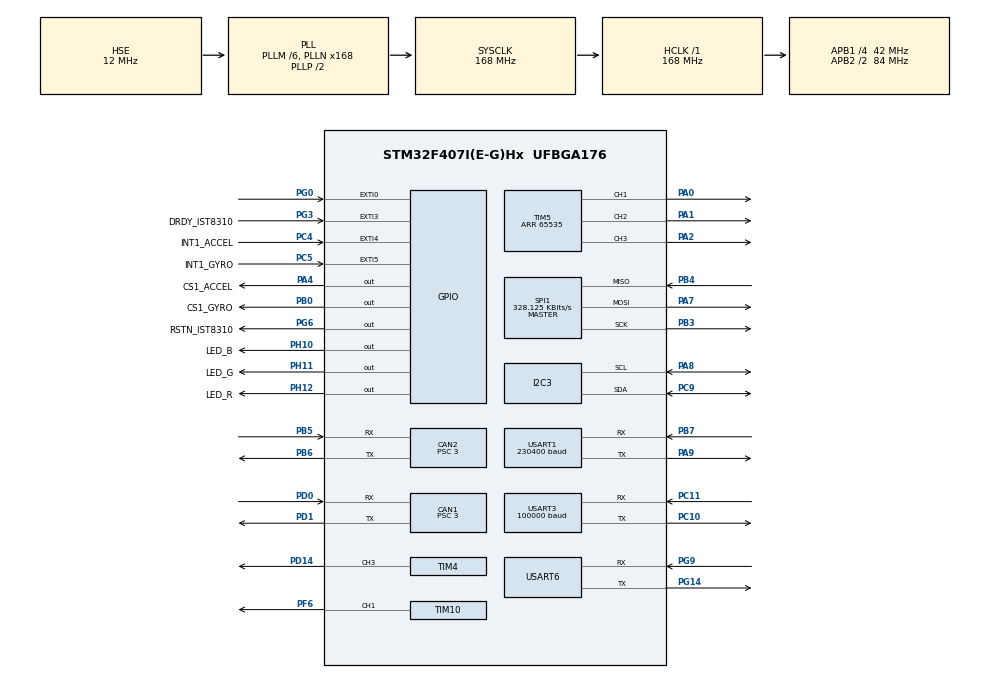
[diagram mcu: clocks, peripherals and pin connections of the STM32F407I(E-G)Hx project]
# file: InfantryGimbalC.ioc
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CAN1.ABOM=ENABLE
CAN1.AWUM=ENABLE
CAN1.BS1=CAN_BS1_10TQ
CAN1.BS2=CAN_BS2_3TQ
CAN1.CalculateBaudRate=1000000
CAN1.CalculateTimeBit=1000
CAN1.CalculateTimeQuantum=71.42857142857143
CAN1.NART=ENABLE
CAN1.Prescaler=3
CAN2.ABOM=ENABLE
CAN2.AWUM=ENABLE
CAN2.BS1=CAN_BS1_10TQ
CAN2.BS2=CAN_BS2_3TQ
CAN2.CalculateBaudRate=1000000
CAN2.CalculateTimeBit=1000
CAN2.CalculateTimeQuantum=71.42857142857143
CAN2.NART=ENABLE
CAN2.Prescaler=3
Dma.Request0=SPI1_RX
Dma.Request1=SPI1_TX
Dma.Request2=USART3_RX
Dma.Request3=USART6_RX
Dma.Request4=USART6_TX
Dma.Request5=USART1_RX
Dma.SPI1_RX.0.Direction=DMA_PERIPH_TO_MEMORY
Dma.SPI1_RX.0.FIFOMode=DMA_FIFOMODE_DISABLE
Dma.SPI1_RX.0.Instance=DMA2_Stream2
Dma.SPI1_RX.0.MemDataAlignment=DMA_MDATAALIGN_BYTE
Dma.SPI1_RX.0.MemInc=DMA_MINC_ENABLE
Dma.SPI1_RX.0.Mode=DMA_NORMAL
Dma.SPI1_RX.0.PeriphDataAlignment=DMA_PDATAALIGN_BYTE
Dma.SPI1_RX.0.PeriphInc=DMA_PINC_DISABLE
Dma.SPI1_RX.0.Priority=DMA_PRIORITY_VERY_HIGH
Dma.SPI1_TX.1.Direction=DMA_MEMORY_TO_PERIPH
Dma.SPI1_TX.1.FIFOMode=DMA_FIFOMODE_DISABLE
Dma.SPI1_TX.1.Instance=DMA2_Stream3
Dma.SPI1_TX.1.MemDataAlignment=DMA_MDATAALIGN_BYTE
Dma.SPI1_TX.1.MemInc=DMA_MINC_ENABLE
Dma.SPI1_TX.1.Mode=DMA_NORMAL
Dma.SPI1_TX.1.PeriphDataAlignment=DMA_PDATAALIGN_BYTE
Dma.SPI1_TX.1.PeriphInc=DMA_PINC_DISABLE
Dma.SPI1_TX.1.Priority=DMA_PRIORITY_HIGH
Dma.USART1_RX.5.Direction=DMA_PERIPH_TO_MEMORY
Dma.USART1_RX.5.FIFOMode=DMA_FIFOMODE_DISABLE
Dma.USART1_RX.5.Instance=DMA2_Stream5
Dma.USART1_RX.5.MemDataAlignment=DMA_MDATAALIGN_BYTE
Dma.USART1_RX.5.MemInc=DMA_MINC_ENABLE
Dma.USART1_RX.5.Mode=DMA_NORMAL
Dma.USART1_RX.5.PeriphDataAlignment=DMA_PDATAALIGN_BYTE
Dma.USART1_RX.5.PeriphInc=DMA_PINC_DISABLE
Dma.USART1_RX.5.Priority=DMA_PRIORITY_LOW
Dma.USART3_RX.2.Direction=DMA_PERIPH_TO_MEMORY
Dma.USART3_RX.2.FIFOMode=DMA_FIFOMODE_DISABLE
Dma.USART3_RX.2.Instance=DMA1_Stream1
Dma.USART3_RX.2.MemDataAlignment=DMA_MDATAALIGN_BYTE
Dma.USART3_RX.2.MemInc=DMA_MINC_ENABLE
Dma.USART3_RX.2.Mode=DMA_NORMAL
Dma.USART3_RX.2.PeriphDataAlignment=DMA_PDATAALIGN_BYTE
Dma.USART3_RX.2.PeriphInc=DMA_PINC_DISABLE
Dma.USART3_RX.2.Priority=DMA_PRIORITY_HIGH
Dma.USART6_RX.3.Direction=DMA_PERIPH_TO_MEMORY
Dma.USART6_RX.3.FIFOMode=DMA_FIFOMODE_DISABLE
Dma.USART6_RX.3.Instance=DMA2_Stream1
Dma.USART6_RX.3.MemDataAlignment=DMA_MDATAALIGN_BYTE
Dma.USART6_RX.3.MemInc=DMA_MINC_ENABLE
Dma.USART6_RX.3.Mode=DMA_CIRCULAR
Dma.USART6_RX.3.PeriphDataAlignment=DMA_PDATAALIGN_BYTE
Dma.USART6_RX.3.PeriphInc=DMA_PINC_DISABLE
Dma.USART6_RX.3.Priority=DMA_PRIORITY_MEDIUM
Dma.USART6_TX.4.Direction=DMA_MEMORY_TO_PERIPH
Dma.USART6_TX.4.FIFOMode=DMA_FIFOMODE_DISABLE
Dma.USART6_TX.4.Instance=DMA2_Stream6
Dma.USART6_TX.4.MemDataAlignment=DMA_MDATAALIGN_BYTE
Dma.USART6_TX.4.MemInc=DMA_MINC_ENABLE
Dma.USART6_TX.4.Mode=DMA_NORMAL
Dma.USART6_TX.4.PeriphDataAlignment=DMA_PDATAALIGN_BYTE
Dma.USART6_TX.4.PeriphInc=DMA_PINC_DISABLE
Dma.USART6_TX.4.Priority=DMA_PRIORITY_MEDIUM
FREERTOS.BinarySemaphores01=RemoteSem,Dynamic,NULL
FREERTOS.Events01=refereeEvent,Dynamic,NULL
FREERTOS.INCLUDE_pcTaskGetTaskName=1
FREERTOS.INCLUDE_xTaskGetHandle=1
FREERTOS.Queues01=can1Queue,512,size10_t,0,Dynamic,NULL,NULL;can2Queue,512,size10_t,0,Dynamic,NULL,NULL
FREERTOS.Tasks01=defaultTask,24,256,StartDefaultTask,Default,NULL,Dynamic,NULL,NULL;ledTask,8,256,Led_Task,As weak,NULL,Dynamic,NULL,NULL;buzzerTask,8,256,Buzzer_Task,As weak,NULL,Dynamic,NULL,NULL;imuTask,55,1024,Gyro_task,As weak,NULL,Dynamic,NULL,NULL;remoteTask,55,256,Remote_Task,As weak,NULL,Dynamic,NULL,NULL;communicateTask,55,256,Communicate_Task,As weak,NULL,Dynamic,NULL,NULL;chassisTask,55,2048,Chassis_Task,As weak,NULL,Dynamic,NULL,NULL;communicate2Tas,55,256,Communicate2_Task,As weak,NULL,Dynamic,NULL,NULL;judgeUnpackTask,55,256,Judge_Unpack_Task,As weak,NULL,Dynamic,NULL,NULL;stuinteractiveT,8,256,StuInteractive_Task,As weak,NULL,Dynamic,NULL,NULL;powerTask,55,256,PowerTask,As weak,NULL,Dynamic,NULL,NULL;communicate3Tas,8,256,Communicate3_Task,As weak,NULL,Dynamic,NULL,NULL;lostCounterTask,8,256,LostCounter_Task,As weak,NULL,Dynamic,NULL,NULL
FREERTOS.configGENERATE_RUN_TIME_STATS=1
FREERTOS.configMINIMAL_STACK_SIZE=256
FREERTOS.configTOTAL_HEAP_SIZE=80000
FREERTOS.configUSE_NEWLIB_REENTRANT=1
I2C3.I2C_Mode=I2C_Fast
IWDG.Prescaler=IWDG_PRESCALER_64
IWDG.Reload=625
Mcu.Family=STM32F4
Mcu.Name=STM32F407I(E-G)Hx
Mcu.Package=UFBGA176
NVIC.CAN1_RX0_IRQn=true\:5\:0\:false\:false\:true\:true\:true\:true\:true
NVIC.CAN2_RX0_IRQn=true\:5\:0\:false\:false\:true\:true\:true\:true\:true
NVIC.DMA1_Stream1_IRQn=true\:5\:0\:false\:false\:true\:true\:false\:true\:true
NVIC.DMA2_Stream1_IRQn=true\:5\:0\:false\:false\:true\:true\:false\:true\:true
NVIC.DMA2_Stream2_IRQn=true\:5\:0\:false\:false\:true\:false\:false\:true\:true
NVIC.DMA2_Stream3_IRQn=true\:5\:0\:false\:false\:true\:true\:false\:true\:true
NVIC.DMA2_Stream5_IRQn=true\:5\:0\:false\:false\:true\:true\:false\:true\:true
NVIC.DMA2_Stream6_IRQn=true\:5\:0\:false\:false\:true\:true\:false\:true\:true
NVIC.EXTI0_IRQn=true\:5\:0\:false\:false\:true\:true\:true\:true\:true
NVIC.EXTI3_IRQn=true\:5\:0\:false\:false\:true\:true\:true\:true\:true
NVIC.EXTI4_IRQn=true\:5\:0\:false\:false\:true\:true\:true\:true\:true
NVIC.EXTI9_5_IRQn=true\:5\:0\:false\:false\:true\:true\:true\:true\:true
NVIC.PriorityGroup=NVIC_PRIORITYGROUP_4
NVIC.TIM7_IRQn=true\:15\:0\:false\:false\:true\:false\:false\:true\:true
NVIC.TimeBase=TIM7_IRQn
NVIC.TimeBaseIP=TIM7
NVIC.USART1_IRQn=true\:5\:0\:false\:false\:true\:true\:true\:true\:true
NVIC.USART3_IRQn=true\:5\:0\:false\:false\:true\:true\:true\:true\:true
NVIC.USART6_IRQn=true\:5\:0\:false\:false\:true\:true\:true\:true\:true
PA0-WKUP.Signal=S_TIM5_CH1
PA1.Signal=S_TIM5_CH2
PA13.Mode=Serial_Wire
PA13.Signal=SYS_JTMS-SWDIO
PA14.Mode=Serial_Wire
PA14.Signal=SYS_JTCK-SWCLK
PA2.Signal=S_TIM5_CH3
PA4.GPIO_Label=CS1_ACCEL
PA4.GPIO_PuPd=GPIO_PULLUP
PA4.GPIO_Speed=GPIO_SPEED_FREQ_HIGH
PA4.PinState=GPIO_PIN_SET
PA4.Signal=GPIO_Output
PA7.Mode=Full_Duplex_Master
PA7.Signal=SPI1_MOSI
PA8.Mode=I2C
PA8.Signal=I2C3_SCL
PA9.Mode=Asynchronous
PA9.Signal=USART1_TX
PB0.GPIO_Label=CS1_GYRO
PB0.GPIO_PuPd=GPIO_PULLUP
PB0.GPIO_Speed=GPIO_SPEED_FREQ_HIGH
PB0.PinState=GPIO_PIN_SET
PB0.Signal=GPIO_Output
PB3.Mode=Full_Duplex_Master
PB3.Signal=SPI1_SCK
PB4.Mode=Full_Duplex_Master
PB4.Signal=SPI1_MISO
PB5.Mode=CAN_Activate
PB5.Signal=CAN2_RX
PB6.Mode=CAN_Activate
PB6.Signal=CAN2_TX
PB7.Mode=Asynchronous
PB7.Signal=USART1_RX
PC10.Mode=Asynchronous
PC10.Signal=USART3_TX
PC11.Mode=Asynchronous
PC11.Signal=USART3_RX
PC4.GPIO_Label=INT1_ACCEL
PC4.GPIO_ModeDefaultEXTI=GPIO_MODE_IT_FALLING
PC4.GPIO_PuPd=GPIO_PULLUP
PC4.Signal=GPXTI4
PC5.GPIO_Label=INT1_GYRO
PC5.GPIO_ModeDefaultEXTI=GPIO_MODE_IT_FALLING
PC5.GPIO_PuPd=GPIO_PULLUP
PC5.Signal=GPXTI5
PC9.Mode=I2C
PC9.Signal=I2C3_SDA
PD0.Mode=CAN_Activate
PD0.Signal=CAN1_RX
PD1.Mode=CAN_Activate
PD1.Signal=CAN1_TX
PD14.Signal=S_TIM4_CH3
PF6.GPIO_PuPd=GPIO_PULLUP
PF6.GPIO_Speed=GPIO_SPEED_FREQ_HIGH
PF6.Signal=S_TIM10_CH1
PG0.GPIO_ModeDefaultEXTI=GPIO_MODE_IT_FALLING
PG0.GPIO_PuPd=GPIO_PULLUP
PG0.Signal=GPXTI0
PG14.Mode=Asynchronous
PG14.Signal=USART6_TX
PG3.GPIO_Label=DRDY_IST8310
PG3.GPIO_ModeDefaultEXTI=GPIO_MODE_IT_FALLING
PG3.GPIO_PuPd=GPIO_PULLUP
PG3.Signal=GPXTI3
PG6.GPIO_Label=RSTN_IST8310
PG6.GPIO_PuPd=GPIO_PULLUP
PG6.GPIO_Speed=GPIO_SPEED_FREQ_MEDIUM
PG6.PinState=GPIO_PIN_SET
PG6.Signal=GPIO_Output
PG9.Mode=Asynchronous
PG9.Signal=USART6_RX
PH0-OSC_IN.Mode=HSE-External-Oscillator
PH0-OSC_IN.Signal=RCC_OSC_IN
PH1-OSC_OUT.Mode=HSE-External-Oscillator
PH1-OSC_OUT.Signal=RCC_OSC_OUT
PH10.GPIO_Label=LED_B
PH10.Signal=GPIO_Output
PH11.GPIO_Label=LED_G
PH11.Signal=GPIO_Output
PH12.GPIO_Label=LED_R
PH12.Signal=GPIO_Output
ProjectManager.HeapSize=0x200
ProjectManager.StackSize=0x400
ProjectManager.TargetToolchain=STM32CubeIDE
RCC.48MHZClocksFreq_Value=84000000
RCC.AHBFreq_Value=168000000
RCC.APB1CLKDivider=RCC_HCLK_DIV4
RCC.APB1Freq_Value=42000000
RCC.APB1TimFreq_Value=84000000
RCC.APB2CLKDivider=RCC_HCLK_DIV2
RCC.APB2Freq_Value=84000000
RCC.APB2TimFreq_Value=168000000
RCC.CortexFreq_Value=168000000
RCC.HCLKFreq_Value=168000000
RCC.HSE_VALUE=12000000
RCC.HSI_VALUE=16000000
RCC.LSE_VALUE=32768
RCC.PLLM=6
RCC.PLLN=168
RCC.PLLSourceVirtual=RCC_PLLSOURCE_HSE
RCC.SYSCLKFreq_VALUE=168000000
RCC.SYSCLKSource=RCC_SYSCLKSOURCE_PLLCLK
RCC.VCOOutputFreq_Value=336000000
SH.S_TIM10_CH1.0=TIM10_CH1,PWM Generation1 CH1
SH.S_TIM4_CH3.0=TIM4_CH3,PWM Generation3 CH3
SH.S_TIM5_CH1.0=TIM5_CH1,PWM Generation1 CH1
SH.S_TIM5_CH2.0=TIM5_CH2,PWM Generation2 CH2
SH.S_TIM5_CH3.0=TIM5_CH3,PWM Generation3 CH3
SPI1.BaudRatePrescaler=SPI_BAUDRATEPRESCALER_256
SPI1.CLKPhase=SPI_PHASE_2EDGE
SPI1.CLKPolarity=SPI_POLARITY_HIGH
SPI1.CalculateBaudRate=328.125 KBits/s
SPI1.Direction=SPI_DIRECTION_2LINES
SPI1.Mode=SPI_MODE_MASTER
SPI1.VirtualType=VM_MASTER
STMicroelectronics.X-CUBE-ALGOBUILD.1.3.0.LibraryCcDSPOoLibraryJjDSPOoLibrary=true
TIM10.Channel=TIM_CHANNEL_1
TIM10.Period=4999
TIM4.Channel-PWM\ Generation3\ CH3=TIM_CHANNEL_3
TIM4.Period=999
TIM4.Prescaler=83
TIM4.Pulse-PWM\ Generation3\ CH3=500
TIM5.Channel-PWM\ Generation1\ CH1=TIM_CHANNEL_1
TIM5.Channel-PWM\ Generation2\ CH2=TIM_CHANNEL_2
TIM5.Channel-PWM\ Generation3\ CH3=TIM_CHANNEL_3
TIM5.Period=65535
USART1.BaudRate=230400
USART1.Mode=MODE_RX
USART1.VirtualMode=VM_ASYNC
USART3.BaudRate=100000
USART3.Mode=MODE_RX
USART3.Parity=PARITY_EVEN
USART3.VirtualMode=VM_ASYNC
USART3.WordLength=WORDLENGTH_9B
USART6.VirtualMode=VM_ASYNC
VP_FREERTOS_VS_CMSIS_V2.Mode=CMSIS_V2
VP_IWDG_VS_IWDG.Mode=IWDG_Activate
VP_STMicroelectronics.X-CUBE-ALGOBUILD_VS_DSPOoLibraryJjLibrary_1.3.0_1.3.0.Mode=DSPOoLibraryJjLibrary
VP_SYS_VS_tim7.Mode=TIM7
VP_TIM10_VS_ClockSourceINT.Mode=Enable_Timer
VP_TIM4_VS_ClockSourceINT.Mode=Internal
VP_TIM5_VS_ClockSourceINT.Mode=Internal
board=custom

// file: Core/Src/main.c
/* USER CODE BEGIN Header */
/**
  ******************************************************************************
  * @file           : main.c
  * @brief          : Main program body
  ******************************************************************************
  * @attention
  *
  * Copyright (c) 2023 STMicroelectronics.
  * All rights reserved.
  *
  * This software is licensed under terms that can be found in the LICENSE file
  * in the root directory of this software component.
  * If no LICENSE file comes with this software, it is provided AS-IS.
  *
  ******************************************************************************
  */
/* USER CODE END Header */
#include "main.h"
#include "cmsis_os.h"
#include "can.h"
#include "dma.h"
#include "i2c.h"
#include "iwdg.h"
#include "spi.h"
#include "tim.h"
#include "usart.h"
#include "gpio.h"

/* USER CODE BEGIN Includes */
#include "BMI088driver.h"
#include "bsp_dwt.h"
#include "bsp_can.h"
/* USER CODE END Includes */

void SystemClock_Config(void);
void MX_FREERTOS_Init(void);

/* USER CODE BEGIN 0 */
uint8_t Buffer[1];
/* USER CODE END 0 */

int main(void)
{
  /* USER CODE BEGIN 1 */
//修复openocd初始化时钟问�??
    __HAL_RCC_SYSCLK_CONFIG(RCC_SYSCLKSOURCE_HSI);
  /* USER CODE END 1 */

  /* MCU Configuration--------------------------------------------------------*/

  /* Reset of all peripherals, Initializes the Flash interface and the Systick. */
  HAL_Init();

  /* Configure the system clock */
  SystemClock_Config();

  /* Initialize all configured peripherals */
  MX_GPIO_Init();
  MX_DMA_Init();
  MX_TIM4_Init();
  MX_SPI1_Init();
  MX_I2C3_Init();
  MX_TIM10_Init();
  MX_TIM5_Init();
  MX_CAN1_Init();
  MX_CAN2_Init();
  MX_USART3_UART_Init();
  MX_USART6_UART_Init();
  MX_IWDG_Init();
  MX_USART1_UART_Init();
  /* USER CODE BEGIN 2 */
    DWT_Init(168);
    while (BMI088_init(&hspi1, 0) != BMI088_NO_ERROR)
        ;
    HAL_TIM_PWM_Start(&htim4,TIM_CHANNEL_3);
    CanInit();
    HAL_UARTEx_ReceiveToIdle_DMA(&huart1,(uint8_t *)Buffer, 1);
   // HAL_UART_Receive_IT(&huart1, (uint8_t *)Buffer, 1);
  /* USER CODE END 2 */

  /* Init scheduler */
  osKernelInitialize();  /* Call init function for freertos objects (in freertos.c) */
  MX_FREERTOS_Init();

  /* Start scheduler */
  osKernelStart();

  /* We should never get here as control is now taken by the scheduler */
  /* Infinite loop */
  while (1)
  {

  }
}

void SystemClock_Config(void)
{
  RCC_OscInitTypeDef RCC_OscInitStruct = {0};
  RCC_ClkInitTypeDef RCC_ClkInitStruct = {0};

  /** Configure the main internal regulator output voltage
  */
  __HAL_RCC_PWR_CLK_ENABLE();
  __HAL_PWR_VOLTAGESCALING_CONFIG(PWR_REGULATOR_VOLTAGE_SCALE1);

  /** Initializes the RCC Oscillators according to the specified parameters
  * in the RCC_OscInitTypeDef structure.
  */
  RCC_OscInitStruct.OscillatorType = RCC_OSCILLATORTYPE_LSI|RCC_OSCILLATORTYPE_HSE;
  RCC_OscInitStruct.HSEState = RCC_HSE_ON;
  RCC_OscInitStruct.LSIState = RCC_LSI_ON;
  RCC_OscInitStruct.PLL.PLLState = RCC_PLL_ON;
  RCC_OscInitStruct.PLL.PLLSource = RCC_PLLSOURCE_HSE;
  RCC_OscInitStruct.PLL.PLLM = 6;
  RCC_OscInitStruct.PLL.PLLN = 168;
  RCC_OscInitStruct.PLL.PLLP = RCC_PLLP_DIV2;
  RCC_OscInitStruct.PLL.PLLQ = 4;
  if (HAL_RCC_OscConfig(&RCC_OscInitStruct) != HAL_OK)
  {
    Error_Handler();
  }

  /** Initializes the CPU, AHB and APB buses clocks
  */
  RCC_ClkInitStruct.ClockType = RCC_CLOCKTYPE_HCLK|RCC_CLOCKTYPE_SYSCLK
                              |RCC_CLOCKTYPE_PCLK1|RCC_CLOCKTYPE_PCLK2;
  RCC_ClkInitStruct.SYSCLKSource = RCC_SYSCLKSOURCE_PLLCLK;
  RCC_ClkInitStruct.AHBCLKDivider = RCC_SYSCLK_DIV1;
  RCC_ClkInitStruct.APB1CLKDivider = RCC_HCLK_DIV4;
  RCC_ClkInitStruct.APB2CLKDivider = RCC_HCLK_DIV2;

  if (HAL_RCC_ClockConfig(&RCC_ClkInitStruct, FLASH_LATENCY_5) != HAL_OK)
  {
    Error_Handler();
  }
}

void HAL_TIM_PeriodElapsedCallback(TIM_HandleTypeDef *htim)
{
  if (htim->Instance == TIM7) {
    HAL_IncTick();
  }
}

void Error_Handler(void)
{
  __disable_irq();
  while (1)
  {
  }
}

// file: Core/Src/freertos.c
/* USER CODE BEGIN Header */
/**
  ******************************************************************************
  * File Name          : freertos.c
  * Description        : Code for freertos applications
  ******************************************************************************
  * @attention
  *
  * Copyright (c) 2023 STMicroelectronics.
  * All rights reserved.
  *
  * This software is licensed under terms that can be found in the LICENSE file
  * in the root directory of this software component.
  * If no LICENSE file comes with this software, it is provided AS-IS.
  *
  ******************************************************************************
  */
/* USER CODE END Header */

#include "FreeRTOS.h"
#include "task.h"
#include "main.h"
#include "cmsis_os.h"

/* Definitions for defaultTask */
osThreadId_t defaultTaskHandle;
const osThreadAttr_t defaultTask_attributes = {
  .name = "defaultTask",
  .stack_size = 256 * 4,
  .priority = (osPriority_t) osPriorityNormal,
};
/* Definitions for ledTask */
osThreadId_t ledTaskHandle;
const osThreadAttr_t ledTask_attributes = {
  .name = "ledTask",
  .stack_size = 256 * 4,
  .priority = (osPriority_t) osPriorityLow,
};
/* Definitions for buzzerTask */
osThreadId_t buzzerTaskHandle;
const osThreadAttr_t buzzerTask_attributes = {
  .name = "buzzerTask",
  .stack_size = 256 * 4,
  .priority = (osPriority_t) osPriorityLow,
};
/* Definitions for imuTask */
osThreadId_t imuTaskHandle;
const osThreadAttr_t imuTask_attributes = {
  .name = "imuTask",
  .stack_size = 1024 * 4,
  .priority = (osPriority_t) osPriorityRealtime7,
};
/* Definitions for remoteTask */
osThreadId_t remoteTaskHandle;
const osThreadAttr_t remoteTask_attributes = {
  .name = "remoteTask",
  .stack_size = 256 * 4,
  .priority = (osPriority_t) osPriorityRealtime7,
};
/* Definitions for communicateTask */
osThreadId_t communicateTaskHandle;
const osThreadAttr_t communicateTask_attributes = {
  .name = "communicateTask",
  .stack_size = 256 * 4,
  .priority = (osPriority_t) osPriorityRealtime7,
};
/* Definitions for chassisTask */
osThreadId_t chassisTaskHandle;
const osThreadAttr_t chassisTask_attributes = {
  .name = "chassisTask",
  .stack_size = 2048 * 4,
  .priority = (osPriority_t) osPriorityRealtime7,
};
/* Definitions for communicate2Tas */
osThreadId_t communicate2TasHandle;
const osThreadAttr_t communicate2Tas_attributes = {
  .name = "communicate2Tas",
  .stack_size = 256 * 4,
  .priority = (osPriority_t) osPriorityRealtime7,
};
/* Definitions for judgeUnpackTask */
osThreadId_t judgeUnpackTaskHandle;
const osThreadAttr_t judgeUnpackTask_attributes = {
  .name = "judgeUnpackTask",
  .stack_size = 256 * 4,
  .priority = (osPriority_t) osPriorityRealtime7,
};
/* Definitions for stuinteractiveT */
osThreadId_t stuinteractiveTHandle;
const osThreadAttr_t stuinteractiveT_attributes = {
  .name = "stuinteractiveT",
  .stack_size = 256 * 4,
  .priority = (osPriority_t) osPriorityLow,
};
/* Definitions for powerTask */
osThreadId_t powerTaskHandle;
const osThreadAttr_t powerTask_attributes = {
  .name = "powerTask",
  .stack_size = 256 * 4,
  .priority = (osPriority_t) osPriorityRealtime7,
};
/* Definitions for communicate3Tas */
osThreadId_t communicate3TasHandle;
const osThreadAttr_t communicate3Tas_attributes = {
  .name = "communicate3Tas",
  .stack_size = 256 * 4,
  .priority = (osPriority_t) osPriorityLow,
};
/* Definitions for lostCounterTask */
osThreadId_t lostCounterTaskHandle;
const osThreadAttr_t lostCounterTask_attributes = {
  .name = "lostCounterTask",
  .stack_size = 256 * 4,
  .priority = (osPriority_t) osPriorityLow,
};
/* Definitions for can1Queue */
osMessageQueueId_t can1QueueHandle;
const osMessageQueueAttr_t can1Queue_attributes = {
  .name = "can1Queue"
};
/* Definitions for can2Queue */
osMessageQueueId_t can2QueueHandle;
const osMessageQueueAttr_t can2Queue_attributes = {
  .name = "can2Queue"
};
/* Definitions for RemoteSem */
osSemaphoreId_t RemoteSemHandle;
const osSemaphoreAttr_t RemoteSem_attributes = {
  .name = "RemoteSem"
};
/* Definitions for refereeEvent */
osEventFlagsId_t refereeEventHandle;
const osEventFlagsAttr_t refereeEvent_attributes = {
  .name = "refereeEvent"
};

void StartDefaultTask(void *argument);
void Led_Task(void *argument);
void Buzzer_Task(void *argument);
void Gyro_task(void *argument);
void Remote_Task(void *argument);
void Communicate_Task(void *argument);
void Chassis_Task(void *argument);
void Communicate2_Task(void *argument);
void Judge_Unpack_Task(void *argument);
void StuInteractive_Task(void *argument);
void PowerTask(void *argument);
void Communicate3_Task(void *argument);
void LostCounter_Task(void *argument);

void MX_FREERTOS_Init(void); /* (MISRA C 2004 rule 8.1) */

/* Hook prototypes */
void configureTimerForRunTimeStats(void);
unsigned long getRunTimeCounterValue(void);

/* USER CODE BEGIN 1 */
/* Functions needed when configGENERATE_RUN_TIME_STATS is on */
__weak void configureTimerForRunTimeStats(void)
{

}

__weak unsigned long getRunTimeCounterValue(void)
{
return 0;
}
/* USER CODE END 1 */

void MX_FREERTOS_Init(void) {

  /* Create the semaphores(s) */
  /* creation of RemoteSem */
  RemoteSemHandle = osSemaphoreNew(1, 1, &RemoteSem_attributes);

  /* Create the queue(s) */
  /* creation of can1Queue */
  can1QueueHandle = osMessageQueueNew (512, sizeof(size10_t), &can1Queue_attributes);

  /* creation of can2Queue */
  can2QueueHandle = osMessageQueueNew (512, sizeof(size10_t), &can2Queue_attributes);

  /* Create the thread(s) */
  /* creation of defaultTask */
  defaultTaskHandle = osThreadNew(StartDefaultTask, NULL, &defaultTask_attributes);

  /* creation of ledTask */
  ledTaskHandle = osThreadNew(Led_Task, NULL, &ledTask_attributes);

  /* creation of buzzerTask */
  buzzerTaskHandle = osThreadNew(Buzzer_Task, NULL, &buzzerTask_attributes);

  /* creation of imuTask */
  imuTaskHandle = osThreadNew(Gyro_task, NULL, &imuTask_attributes);

  /* creation of remoteTask */
  remoteTaskHandle = osThreadNew(Remote_Task, NULL, &remoteTask_attributes);

  /* creation of communicateTask */
  communicateTaskHandle = osThreadNew(Communicate_Task, NULL, &communicateTask_attributes);

  /* creation of chassisTask */
  chassisTaskHandle = osThreadNew(Chassis_Task, NULL, &chassisTask_attributes);

  /* creation of communicate2Tas */
  communicate2TasHandle = osThreadNew(Communicate2_Task, NULL, &communicate2Tas_attributes);

  /* creation of judgeUnpackTask */
  judgeUnpackTaskHandle = osThreadNew(Judge_Unpack_Task, NULL, &judgeUnpackTask_attributes);

  /* creation of stuinteractiveT */
  stuinteractiveTHandle = osThreadNew(StuInteractive_Task, NULL, &stuinteractiveT_attributes);

  /* creation of powerTask */
  powerTaskHandle = osThreadNew(PowerTask, NULL, &powerTask_attributes);

  /* creation of communicate3Tas */
  communicate3TasHandle = osThreadNew(Communicate3_Task, NULL, &communicate3Tas_attributes);

  /* creation of lostCounterTask */
  lostCounterTaskHandle = osThreadNew(LostCounter_Task, NULL, &lostCounterTask_attributes);

  /* Create the event(s) */
  /* creation of refereeEvent */
  refereeEventHandle = osEventFlagsNew(&refereeEvent_attributes);

}

void StartDefaultTask(void *argument)
{
  for(;;)
  {
    osDelay(1);
  }
}

__weak void Led_Task(void *argument)
{
  for(;;)
  {
    osDelay(1);
  }
}

__weak void Buzzer_Task(void *argument)
{
  for(;;)
  {
    osDelay(1);
  }
}

__weak void Gyro_task(void *argument)
{
  for(;;)
  {
    osDelay(1);
  }
}

__weak void Remote_Task(void *argument)
{
  for(;;)
  {
    osDelay(1);
  }
}

__weak void Communicate_Task(void *argument)
{
  for(;;)
  {
    osDelay(1);
  }
}

__weak void Chassis_Task(void *argument)
{
  for(;;)
  {
    osDelay(1);
  }
}

__weak void Communicate2_Task(void *argument)
{
  for(;;)
  {
    osDelay(1);
  }
}

__weak void Judge_Unpack_Task(void *argument)
{
  for(;;)
  {
    osDelay(1);
  }
}

__weak void StuInteractive_Task(void *argument)
{
  for(;;)
  {
    osDelay(1);
  }
}

__weak void PowerTask(void *argument)
{
  for(;;)
  {
    osDelay(1);
  }
}

__weak void Communicate3_Task(void *argument)
{
  for(;;)
  {
    osDelay(1);
  }
}

__weak void LostCounter_Task(void *argument)
{
  for(;;)
  {
    osDelay(1);
  }
}
